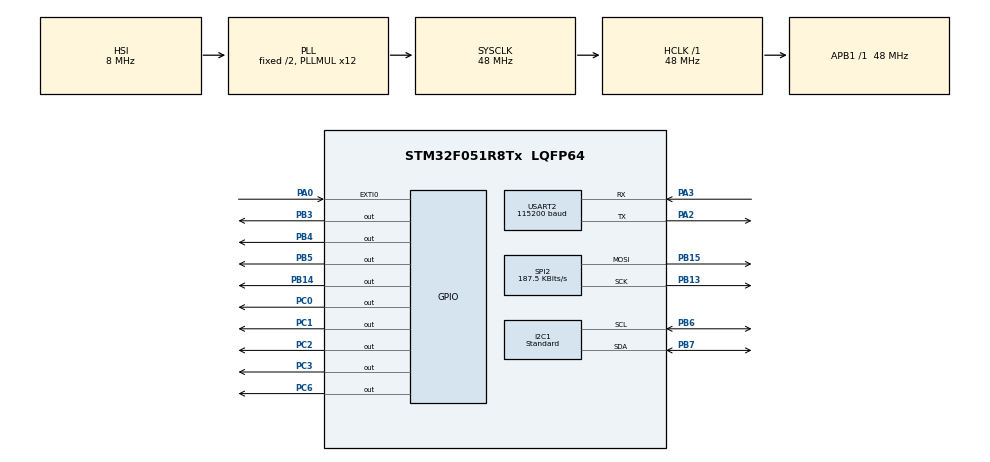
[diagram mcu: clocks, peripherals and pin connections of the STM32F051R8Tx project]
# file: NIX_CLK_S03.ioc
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Dma.Request0=USART2_TX
Dma.USART2_TX.0.Direction=DMA_MEMORY_TO_PERIPH
Dma.USART2_TX.0.Instance=DMA1_Channel4
Dma.USART2_TX.0.MemDataAlignment=DMA_MDATAALIGN_BYTE
Dma.USART2_TX.0.MemInc=DMA_MINC_ENABLE
Dma.USART2_TX.0.Mode=DMA_NORMAL
Dma.USART2_TX.0.PeriphDataAlignment=DMA_PDATAALIGN_BYTE
Dma.USART2_TX.0.PeriphInc=DMA_PINC_DISABLE
Dma.USART2_TX.0.Priority=DMA_PRIORITY_LOW
I2C1.I2C_Speed_Mode=I2C_Standard
I2C1.Timing=0x20303E5D
Mcu.Family=STM32F0
Mcu.Name=STM32F051R8Tx
Mcu.Package=LQFP64
NVIC.DMA1_Channel4_5_IRQn=true\:0\:0\:false\:false\:true\:false\:true
NVIC.EXTI0_1_IRQn=true\:1\:0\:true\:false\:true\:true\:true
NVIC.USART2_IRQn=true\:2\:0\:true\:false\:true\:true\:true
PA0.GPIO_PuPd=GPIO_PULLUP
PA0.Signal=GPXTI0
PA2.Mode=Asynchronous
PA2.Signal=USART2_TX
PA3.Mode=Asynchronous
PA3.Signal=USART2_RX
PB13.Mode=TX_Only_Simplex_Unidirect_Master
PB13.Signal=SPI2_SCK
PB14.Signal=GPIO_Output
PB15.Mode=TX_Only_Simplex_Unidirect_Master
PB15.Signal=SPI2_MOSI
PB3.Signal=GPIO_Output
PB4.Signal=GPIO_Output
PB5.Signal=GPIO_Output
PB6.Mode=I2C
PB6.Signal=I2C1_SCL
PB7.Mode=I2C
PB7.Signal=I2C1_SDA
PC0.Signal=GPIO_Output
PC1.Signal=GPIO_Output
PC2.Signal=GPIO_Output
PC3.Signal=GPIO_Output
PC6.Signal=GPIO_Output
ProjectManager.HeapSize=0x200
ProjectManager.StackSize=0x400
ProjectManager.TargetToolchain=TrueSTUDIO
RCC.AHBFreq_Value=48000000
RCC.APB1Freq_Value=48000000
RCC.APB1TimFreq_Value=48000000
RCC.HCLKFreq_Value=48000000
RCC.I2c1ClockSelection=RCC_I2C1CLKSOURCE_SYSCLK
RCC.PLLMUL=RCC_PLL_MUL12
RCC.SYSCLKFreq_VALUE=48000000
RCC.SYSCLKSource=RCC_SYSCLKSOURCE_PLLCLK
SPI2.BaudRatePrescaler=SPI_BAUDRATEPRESCALER_256
SPI2.CLKPolarity=SPI_POLARITY_HIGH
SPI2.CalculateBaudRate=187.5 KBits/s
SPI2.Direction=SPI_DIRECTION_2LINES
SPI2.Mode=SPI_MODE_MASTER
SPI2.VirtualType=VM_MASTER
USART2.BaudRate=115200
USART2.VirtualMode-Asynchronous=VM_ASYNC
board=custom

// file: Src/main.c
/* USER CODE BEGIN Header */
/**
 ******************************************************************************
 * @file           : main.c
 * @brief          : Main program body
 ******************************************************************************
 * @attention
 *
 * <h2><center>&copy; Copyright (c) 2020 STMicroelectronics.
 * All rights reserved.</center></h2>
 *
 * This software component is licensed by ST under BSD 3-Clause license,
 * the "License"; You may not use this file except in compliance with the
 * License. You may obtain a copy of the License at:
 *                        opensource.org/licenses/BSD-3-Clause
 *
 ******************************************************************************
 */
/* USER CODE END Header */

#include "main.h"
#include "dma.h"
#include "i2c.h"
#include "spi.h"
#include "usart.h"
#include "gpio.h"

/* USER CODE BEGIN Includes */
#include "shift_reg.h"
#include "ESP32.h"
#include <string.h>
#include <stdio.h>
#include <stdbool.h>

/* USER CODE END Includes */

void SystemClock_Config(void);

int main(void)
{

  /* MCU Configuration--------------------------------------------------------*/

  /* Reset of all peripherals, Initializes the Flash interface and the Systick. */
   HAL_Init();

  /* Configure the system clock */
  SystemClock_Config();

  /* Initialize all configured peripherals */
  MX_GPIO_Init();
  MX_I2C1_Init();
  MX_SPI2_Init();
  MX_USART2_UART_Init();
  MX_DMA_Init();
  /* USER CODE BEGIN 2 */
	HAL_GPIO_WritePin(GPIOC, GPIO_PIN_6, 0);
	uint8_t RTC_config[2];
	RTC_config[0] = 0xE;
	RTC_config[1] = 0x0;
	HAL_I2C_Master_Transmit(&hi2c1, 0x68 << 1, RTC_config, 3, 50);

	WiFiConnect();

	ESPSyncToRTC();

  /* USER CODE END 2 */

  /* Infinite loop */
	while (1)
	{

	}
}

void SystemClock_Config(void)
{
  RCC_OscInitTypeDef RCC_OscInitStruct = {0};
  RCC_ClkInitTypeDef RCC_ClkInitStruct = {0};
  RCC_PeriphCLKInitTypeDef PeriphClkInit = {0};

  /** Initializes the CPU, AHB and APB busses clocks
  */
  RCC_OscInitStruct.OscillatorType = RCC_OSCILLATORTYPE_HSI;
  RCC_OscInitStruct.HSIState = RCC_HSI_ON;
  RCC_OscInitStruct.HSICalibrationValue = RCC_HSICALIBRATION_DEFAULT;
  RCC_OscInitStruct.PLL.PLLState = RCC_PLL_ON;
  RCC_OscInitStruct.PLL.PLLSource = RCC_PLLSOURCE_HSI;
  RCC_OscInitStruct.PLL.PLLMUL = RCC_PLL_MUL12;
  RCC_OscInitStruct.PLL.PREDIV = RCC_PREDIV_DIV1;
  if (HAL_RCC_OscConfig(&RCC_OscInitStruct) != HAL_OK)
  {
    Error_Handler();
  }
  /** Initializes the CPU, AHB and APB busses clocks
  */
  RCC_ClkInitStruct.ClockType = RCC_CLOCKTYPE_HCLK|RCC_CLOCKTYPE_SYSCLK
                              |RCC_CLOCKTYPE_PCLK1;
  RCC_ClkInitStruct.SYSCLKSource = RCC_SYSCLKSOURCE_PLLCLK;
  RCC_ClkInitStruct.AHBCLKDivider = RCC_SYSCLK_DIV1;
  RCC_ClkInitStruct.APB1CLKDivider = RCC_HCLK_DIV1;

  if (HAL_RCC_ClockConfig(&RCC_ClkInitStruct, FLASH_LATENCY_1) != HAL_OK)
  {
    Error_Handler();
  }
  PeriphClkInit.PeriphClockSelection = RCC_PERIPHCLK_I2C1;
  PeriphClkInit.I2c1ClockSelection = RCC_I2C1CLKSOURCE_SYSCLK;
  if (HAL_RCCEx_PeriphCLKConfig(&PeriphClkInit) != HAL_OK)
  {
    Error_Handler();
  }
}

void Error_Handler(void)
{
}

/************************ (C) COPYRIGHT STMicroelectronics *****END OF FILE****/
